# PIC32MX470F512L register map
Registers are 32-bit, access not given, reset 0x0 unless marked. A register's access mark holds for its fields unless they carry their own. Offsets are from the block's base; [hi:lo] are bit positions; 'fields as' and 'values as' point back to an identical list.

## UART1 — UART1 peripheral
Base 0xBF806000
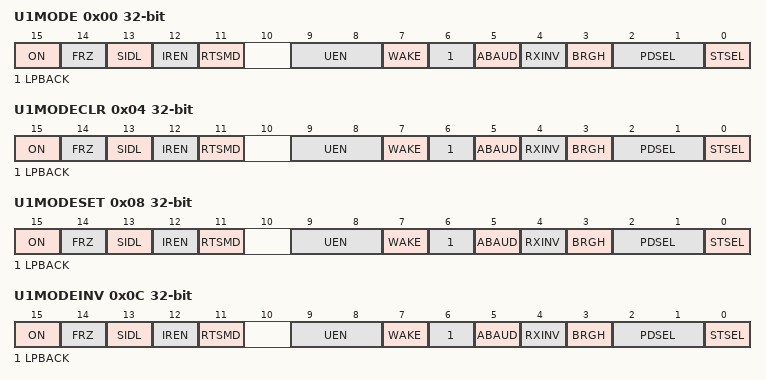
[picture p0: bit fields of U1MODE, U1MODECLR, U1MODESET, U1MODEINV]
0x00 U1MODE
  [15] ON, [14] FRZ, [13] SIDL, [12] IREN, [11] RTSMD, [9:8] UEN, [7] WAKE, [6] LPBACK, [5] ABAUD, [4] RXINV, [3] BRGH, [2:1] PDSEL, [0] STSEL
0x04 U1MODECLR
  fields as U1MODE
0x08 U1MODESET
  fields as U1MODE
0x0C U1MODEINV
  fields as U1MODE
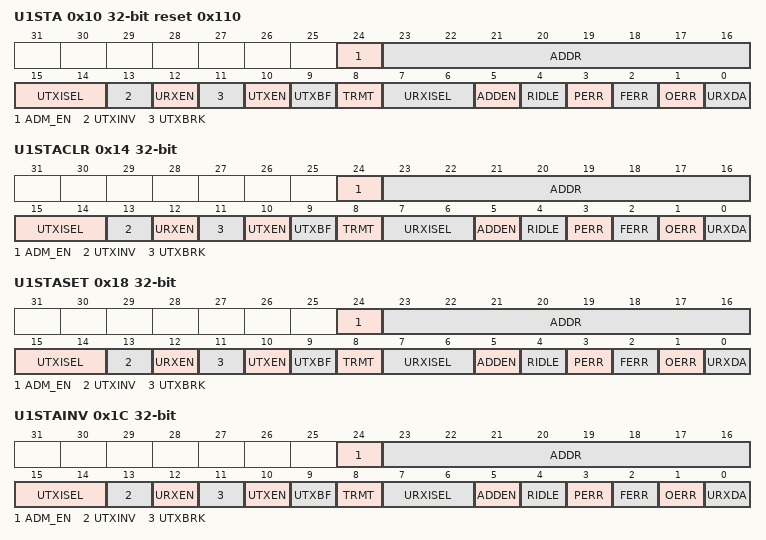
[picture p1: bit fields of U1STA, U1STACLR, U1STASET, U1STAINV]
0x10 U1STA reset 0x110
  [24] ADM_EN, [23:16] ADDR, [15:14] UTXISEL, [13] UTXINV, [12] URXEN, [11] UTXBRK, [10] UTXEN, [9] UTXBF, [8] TRMT, [7:6] URXISEL, [5] ADDEN, [4] RIDLE, [3] PERR, [2] FERR, [1] OERR, [0] URXDA
0x14 U1STACLR
  fields as U1STA
0x18 U1STASET
  fields as U1STA
0x1C U1STAINV
  fields as U1STA
0x20 U1TXREG
  [8:0] U1TXREG
0x30 U1RXREG
  [8:0] U1RXREG
0x40 U1BRG
  [15:0] BRG
0x44 U1BRGCLR
  [15:0] BRG
0x48 U1BRGSET
  [15:0] BRG
0x4C U1BRGINV
  [15:0] BRG

## UART2 — UART2 peripheral
Base 0xBF806200
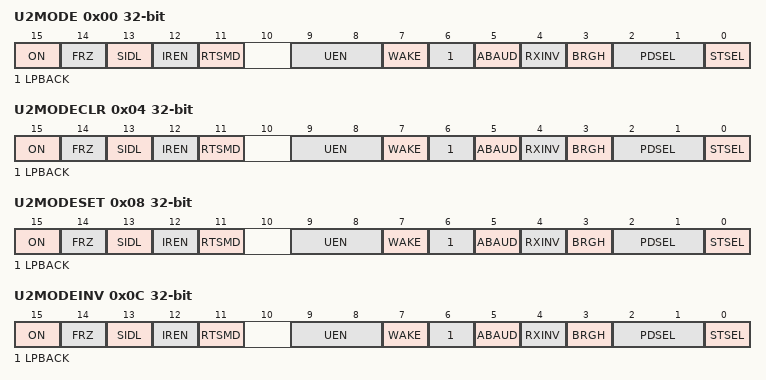
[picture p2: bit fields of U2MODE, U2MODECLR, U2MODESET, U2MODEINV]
0x00 U2MODE
  [15] ON, [14] FRZ, [13] SIDL, [12] IREN, [11] RTSMD, [9:8] UEN, [7] WAKE, [6] LPBACK, [5] ABAUD, [4] RXINV, [3] BRGH, [2:1] PDSEL, [0] STSEL
0x04 U2MODECLR
  fields as U2MODE
0x08 U2MODESET
  fields as U2MODE
0x0C U2MODEINV
  fields as U2MODE
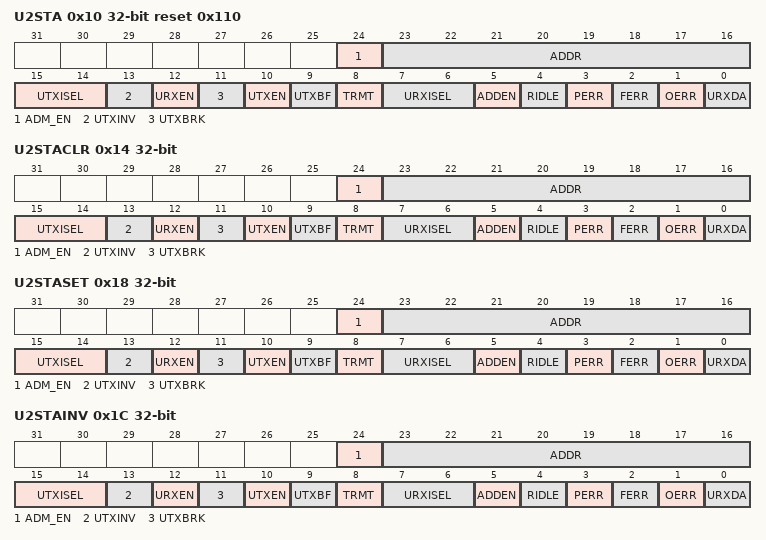
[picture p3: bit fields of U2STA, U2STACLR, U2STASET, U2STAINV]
0x10 U2STA reset 0x110
  [24] ADM_EN, [23:16] ADDR, [15:14] UTXISEL, [13] UTXINV, [12] URXEN, [11] UTXBRK, [10] UTXEN, [9] UTXBF, [8] TRMT, [7:6] URXISEL, [5] ADDEN, [4] RIDLE, [3] PERR, [2] FERR, [1] OERR, [0] URXDA
0x14 U2STACLR
  fields as U2STA
0x18 U2STASET
  fields as U2STA
0x1C U2STAINV
  fields as U2STA
0x20 U2TXREG
  [8:0] U2TXREG
0x30 U2RXREG
  [8:0] U2RXREG
0x40 U2BRG
  [15:0] BRG
0x44 U2BRGCLR
  [15:0] BRG
0x48 U2BRGSET
  [15:0] BRG
0x4C U2BRGINV
  [15:0] BRG

## UART3 — UART3 peripheral
Base 0xBF806400
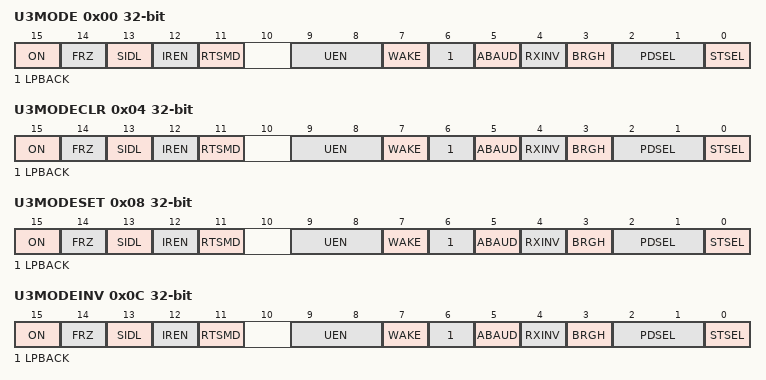
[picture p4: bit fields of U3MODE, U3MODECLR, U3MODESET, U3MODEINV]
0x00 U3MODE
  [15] ON, [14] FRZ, [13] SIDL, [12] IREN, [11] RTSMD, [9:8] UEN, [7] WAKE, [6] LPBACK, [5] ABAUD, [4] RXINV, [3] BRGH, [2:1] PDSEL, [0] STSEL
0x04 U3MODECLR
  fields as U3MODE
0x08 U3MODESET
  fields as U3MODE
0x0C U3MODEINV
  fields as U3MODE
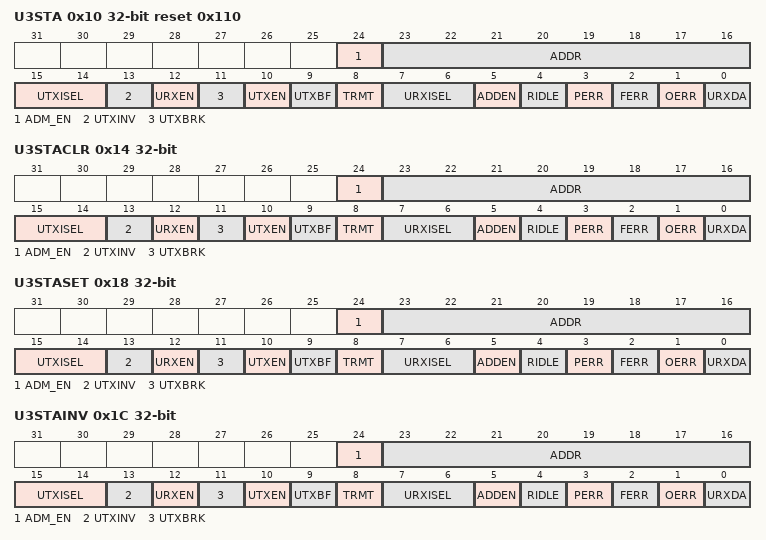
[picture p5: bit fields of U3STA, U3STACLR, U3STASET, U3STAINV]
0x10 U3STA reset 0x110
  [24] ADM_EN, [23:16] ADDR, [15:14] UTXISEL, [13] UTXINV, [12] URXEN, [11] UTXBRK, [10] UTXEN, [9] UTXBF, [8] TRMT, [7:6] URXISEL, [5] ADDEN, [4] RIDLE, [3] PERR, [2] FERR, [1] OERR, [0] URXDA
0x14 U3STACLR
  fields as U3STA
0x18 U3STASET
  fields as U3STA
0x1C U3STAINV
  fields as U3STA
0x20 U3TXREG
  [8:0] U3TXREG
0x30 U3RXREG
  [8:0] U3RXREG
0x40 U3BRG
  [15:0] BRG
0x44 U3BRGCLR
  [15:0] BRG
0x48 U3BRGSET
  [15:0] BRG
0x4C U3BRGINV
  [15:0] BRG

## UART4 — UART4 peripheral
Base 0xBF806600
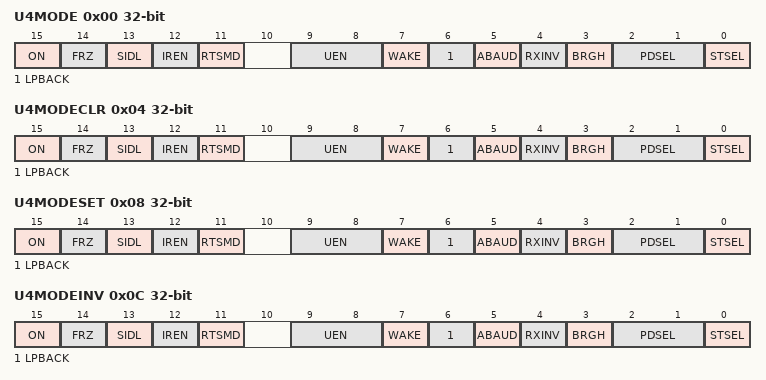
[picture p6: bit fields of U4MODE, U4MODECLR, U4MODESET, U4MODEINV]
0x00 U4MODE
  [15] ON, [14] FRZ, [13] SIDL, [12] IREN, [11] RTSMD, [9:8] UEN, [7] WAKE, [6] LPBACK, [5] ABAUD, [4] RXINV, [3] BRGH, [2:1] PDSEL, [0] STSEL
0x04 U4MODECLR
  fields as U4MODE
0x08 U4MODESET
  fields as U4MODE
0x0C U4MODEINV
  fields as U4MODE
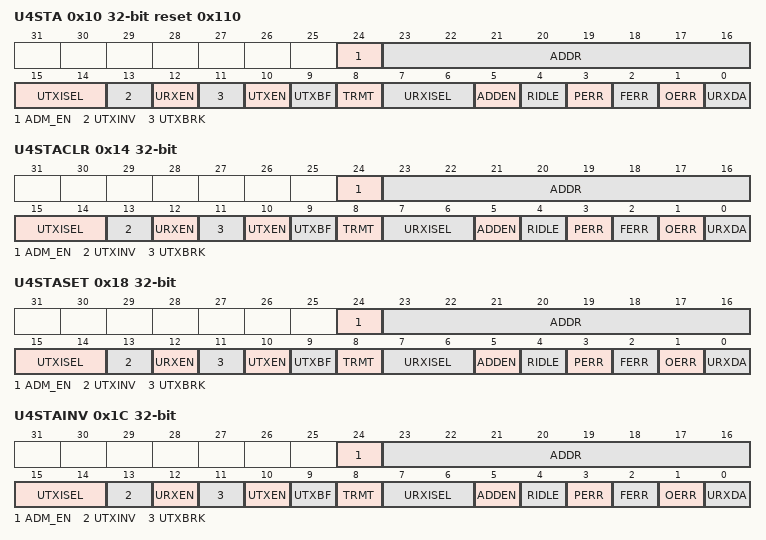
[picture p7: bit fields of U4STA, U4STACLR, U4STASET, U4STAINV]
0x10 U4STA reset 0x110
  [24] ADM_EN, [23:16] ADDR, [15:14] UTXISEL, [13] UTXINV, [12] URXEN, [11] UTXBRK, [10] UTXEN, [9] UTXBF, [8] TRMT, [7:6] URXISEL, [5] ADDEN, [4] RIDLE, [3] PERR, [2] FERR, [1] OERR, [0] URXDA
0x14 U4STACLR
  fields as U4STA
0x18 U4STASET
  fields as U4STA
0x1C U4STAINV
  fields as U4STA
0x20 U4TXREG
  [8:0] U4TXREG
0x30 U4RXREG
  [8:0] U4RXREG
0x40 U4BRG
  [15:0] BRG
0x44 U4BRGCLR
  [15:0] BRG
0x48 U4BRGSET
  [15:0] BRG
0x4C U4BRGINV
  [15:0] BRG

## UART5 — UART5 peripheral
Base 0xBF806800
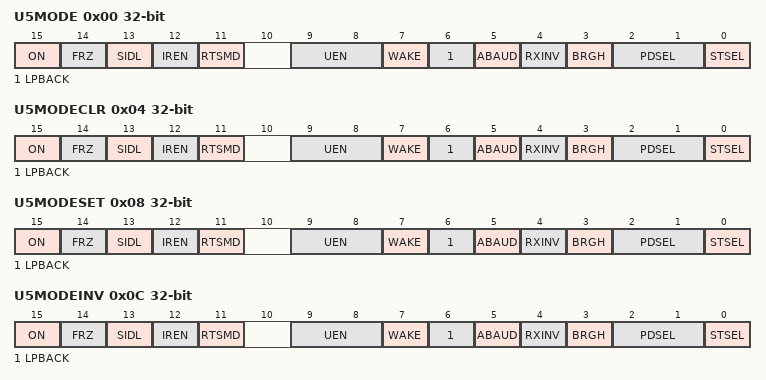
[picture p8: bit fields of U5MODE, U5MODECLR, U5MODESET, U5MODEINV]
0x00 U5MODE
  [15] ON, [14] FRZ, [13] SIDL, [12] IREN, [11] RTSMD, [9:8] UEN, [7] WAKE, [6] LPBACK, [5] ABAUD, [4] RXINV, [3] BRGH, [2:1] PDSEL, [0] STSEL
0x04 U5MODECLR
  fields as U5MODE
0x08 U5MODESET
  fields as U5MODE
0x0C U5MODEINV
  fields as U5MODE
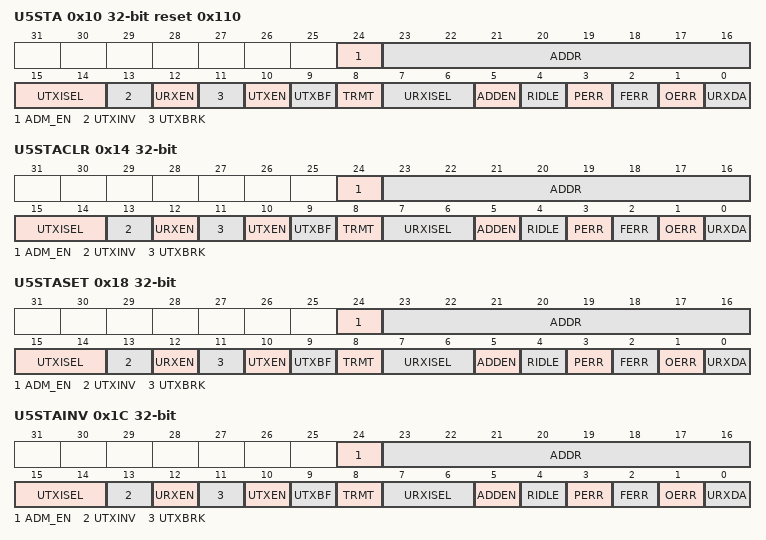
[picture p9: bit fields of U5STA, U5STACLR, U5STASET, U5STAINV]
0x10 U5STA reset 0x110
  [24] ADM_EN, [23:16] ADDR, [15:14] UTXISEL, [13] UTXINV, [12] URXEN, [11] UTXBRK, [10] UTXEN, [9] UTXBF, [8] TRMT, [7:6] URXISEL, [5] ADDEN, [4] RIDLE, [3] PERR, [2] FERR, [1] OERR, [0] URXDA
0x14 U5STACLR
  fields as U5STA
0x18 U5STASET
  fields as U5STA
0x1C U5STAINV
  fields as U5STA
0x20 U5TXREG
  [8:0] U5TXREG
0x30 U5RXREG
  [8:0] U5RXREG
0x40 U5BRG
  [15:0] BRG
0x44 U5BRGCLR
  [15:0] BRG
0x48 U5BRGSET
  [15:0] BRG
0x4C U5BRGINV
  [15:0] BRG
